# headsail register map
Vendor: tuni.fi; File version: 1.1
CPU: other r1p0, little endian, no MPU, no FPU, vendor SysTick, 2 interrupt priority bits
Registers are 32-bit, read-write, no defined reset value unless marked. A register's access mark holds for its fields unless they carry their own. Offsets are from the block's base; [hi:lo] are bit positions; lines under a group give offsets from that group; <NAME> marks a mode.

## C2C_config
Base 0x1FFB00000
0x00 Configuration_Registers group
  0x00 ID ro reset 0x1234ABCD — ID register. Constant ID value
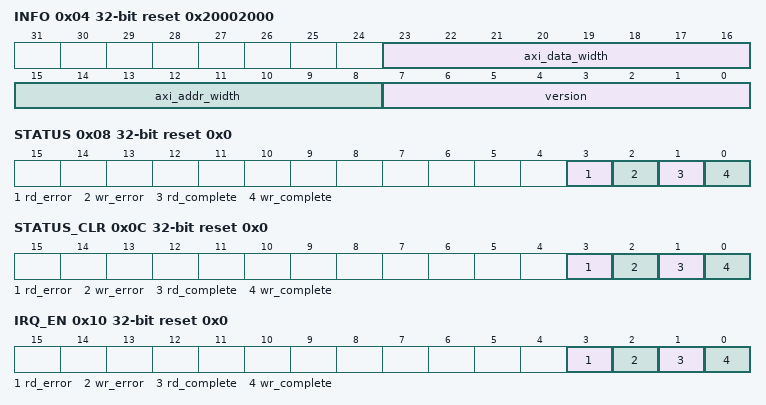
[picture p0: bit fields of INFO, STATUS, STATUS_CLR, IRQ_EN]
  0x04 INFO ro reset 0x20002000 (reset mask 0xFF00FF00) — Version number - AXI Address width - AXI Data width-Reserved
    [23:16] axi_data_width
    [15:8] axi_addr_width — AXI Address Width
    [7:0] version — Version number
  0x08 STATUS ro reset 0x0 — Holds status flags. Each Status Flag can either be cleared by writing to the STATUS_CLR register or when the STATUS register is read (must be configured)
    [3] rd_error — Status flag for read transfer error
    [2] wr_error — Status flag for write transfer error
    [1] rd_complete — Status flag for read transfer completion
    [0] wr_complete — Status flag for write transfer completion
  0x0C STATUS_CLR reset 0x0 — Acknowledging status register. Clearing each respective one by setting corresponding bit
    [3] rd_error — Acknowledging rd_error status bit. Clearing rd_error status flag by setting '1'
    [2] wr_error — Acknowledging wr_error status bit. Clearing wr_error status flag by setting '1'
    [1] rd_complete — Acknowledging rd_complete status bit. Clearing rd_complete status flag by setting '1'
    [0] wr_complete — Acknowledging wr_complete status bit. Clearing wr_complete status flag by setting '1'
  0x10 IRQ_EN reset 0x0 (reset mask 0xD) — Configuring which of the interrupts are routed to the IRQ pin. Enabling each intterupt signal by setting corresponding bit. All of the interrupts can be enabled and disabled independent from each other.
    [3] rd_error — Configuring rd_error interrupt is routed to the IRQ pin by setting '1'
    [2] wr_error — Configuring wr_error interrupt is routed to the IRQ pin by setting '1'
    [1] rd_complete — Configuring rd_complete interrupt is routed to the IRQ pin by setting '1'
    [0] wr_complete — Configuring wr_complete interrupt is routed to the IRQ pin by setting '1'
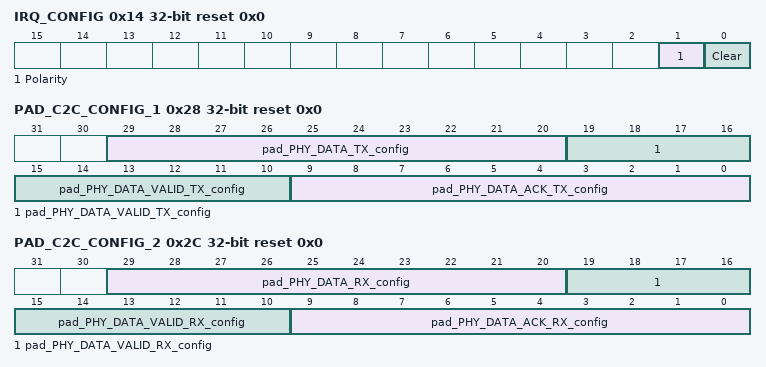
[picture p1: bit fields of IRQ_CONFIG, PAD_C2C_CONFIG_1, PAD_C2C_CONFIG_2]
  0x14 IRQ_CONFIG reset 0x0 — Configures the state (active high/low) and clearing conditions for the IRQ pin. Clear: '0' = Use STATUS_CLR to clear '1' = Auto Clear on Read of STATUS register Polarity: '0' = IRQ active low '1' = IRQ active high
    [1] Polarity — Polarity: '0' = IRQ active low '1' = IRQ active high
    [0] Clear — Clear: '0' = Use STATUS_CLR to clear '1' = Auto Clear on Read of STATUS register
  0x18 ADDRESS_MAPPING_TX reset 0x0 — Address Mapping for AXI4 slave interface. It provides a subset of the bits that will be used as a map value
  0x1C ADDRESS_MASKING_TX reset 0xFFFFFFFF — Address Masking for AXI4 slave interface. It specifies a bitmask. address_masking (i) = 1 : address_out(i) <=address_in(i) address_masking (i) = 0 : address_out(i) <= address_mapping(i) E.g. address_in = 0x70007000 address_masking= 0x0000FFFF address_mapping = 0xABCD0000 address_out = 0xABCD7000
  0x20 ADDRESS_MAPPING_RX reset 0x0 — Address Mapping for AXI4 master interface. It provides a subset of the bits that will be used as a map value
  0x24 ADDRESS_MASKING_RX reset 0xFFFFFFFF — Address Masking for AXI4 master interface. It specifies a bitmask. address_masking (i) = 1 : address_out(i) <=address_in(i) address_masking (i) = 0 : address_out(i) <= address_mapping(i) E.g. address_in = 0x70007000 address_masking= 0x0000FFFF address_mapping = 0xABCD0000 address_out = 0xABCD7000
  0x28 PAD_C2C_CONFIG_1 reset 0x0 (reset mask 0xFFC03FF0) — PAD configuration Register 1. It is used to perform proper configuration for the corresponding pads of the I/O ports 10 bits per PAD configuration 0: drive strenght / 1: drive strenght / 2: schmitt trigger / 3: schmitt trigger / 4: rate / 5: output en(0) / 6: hold / 7: pull enable / 8: pd(0)/pu(1) / 9: input en(1)
    [29:20] pad_PHY_DATA_TX_config — 0: drive strenght / 1: drive strenght / 2: schmitt trigger / 3: schmitt trigger / 4: rate / 5: output en(0) / 6: hold / 7: pull enable / 8: pd(0)/pu(1) / 9: input en(1)
    [19:10] pad_PHY_DATA_VALID_TX_config — 0: drive strenght / 1: drive strenght / 2: schmitt trigger / 3: schmitt trigger / 4: rate / 5: output en(0) / 6: hold / 7: pull enable / 8: pd(0)/pu(1) / 9: input en(1)
    [9:0] pad_PHY_DATA_ACK_TX_config — 0: drive strenght / 1: drive strenght / 2: schmitt trigger / 3: schmitt trigger / 4: rate / 5: output en(0) / 6: hold / 7: pull enable / 8: pd(0)/pu(1) / 9: input en(1)
  0x2C PAD_C2C_CONFIG_2 reset 0x0 (reset mask 0xFFC03FF0) — PAD configuration Register 2. It is used to perform proper configuration for the corresponding pads of the I/O ports 10 bits per PAD configuration 0: drive strenght / 1: drive strenght / 2: schmitt trigger / 3: schmitt trigger / 4: rate / 5: output en(0) / 6: hold / 7: pull enable / 8: pd(0)/pu(1) / 9: input en(1)
    [29:20] pad_PHY_DATA_RX_config — 0: drive strenght / 1: drive strenght / 2: schmitt trigger / 3: schmitt trigger / 4: rate / 5: output en(0) / 6: hold / 7: pull enable / 8: pd(0)/pu(1) / 9: input en(1)
    [19:10] pad_PHY_DATA_VALID_RX_config — 0: drive strenght / 1: drive strenght / 2: schmitt trigger / 3: schmitt trigger / 4: rate / 5: output en(0) / 6: hold / 7: pull enable / 8: pd(0)/pu(1) / 9: input en(1)
    [9:0] pad_PHY_DATA_ACK_RX_config — 0: drive strenght / 1: drive strenght / 2: schmitt trigger / 3: schmitt trigger / 4: rate / 5: output en(0) / 6: hold / 7: pull enable / 8: pd(0)/pu(1) / 9: input en(1)
